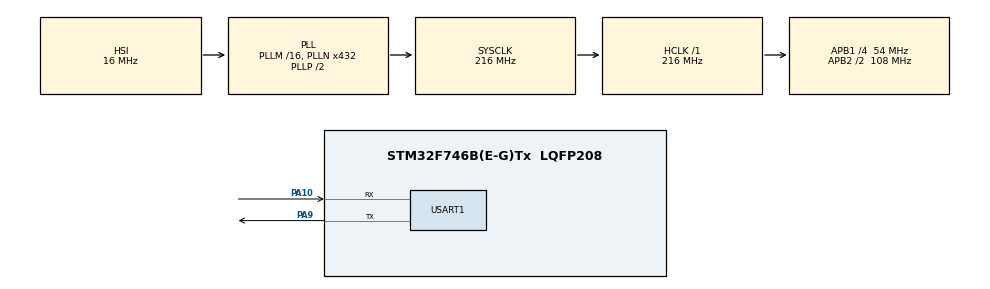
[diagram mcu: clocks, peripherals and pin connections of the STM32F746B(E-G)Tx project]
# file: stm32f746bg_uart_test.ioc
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Mcu.Family=STM32F7
Mcu.Name=STM32F746B(E-G)Tx
Mcu.Package=LQFP208
NVIC.PriorityGroup=NVIC_PRIORITYGROUP_4
PA10.Mode=Asynchronous
PA10.Signal=USART1_RX
PA13.Mode=Serial_Wire
PA13.Signal=SYS_JTMS-SWDIO
PA14.Mode=Serial_Wire
PA14.Signal=SYS_JTCK-SWCLK
PA9.Mode=Asynchronous
PA9.Signal=USART1_TX
ProjectManager.HeapSize=0x200
ProjectManager.StackSize=0x400
ProjectManager.TargetToolchain=EWARM V8
RCC.AHBFreq_Value=216000000
RCC.APB1CLKDivider=RCC_HCLK_DIV4
RCC.APB1Freq_Value=54000000
RCC.APB1TimFreq_Value=108000000
RCC.APB2CLKDivider=RCC_HCLK_DIV2
RCC.APB2Freq_Value=108000000
RCC.APB2TimFreq_Value=216000000
RCC.CortexFreq_Value=216000000
RCC.HCLKFreq_Value=216000000
RCC.HSE_VALUE=25000000
RCC.HSI_VALUE=16000000
RCC.LSE_VALUE=32768
RCC.PLLN=432
RCC.SYSCLKFreq_VALUE=216000000
RCC.SYSCLKSource=RCC_SYSCLKSOURCE_PLLCLK
RCC.USBFreq_Value=216000000
RCC.VCOOutputFreq_Value=432000000
USART1.VirtualMode-Asynchronous=VM_ASYNC
board=custom

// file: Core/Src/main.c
/* USER CODE BEGIN Header */
/**
  ******************************************************************************
  * @file           : main.c
  * @brief          : Main program body
  ******************************************************************************
  * @attention
  *
  * <h2><center>&copy; Copyright (c) 2020 STMicroelectronics.
  * All rights reserved.</center></h2>
  *
  * This software component is licensed by ST under BSD 3-Clause license,
  * the "License"; You may not use this file except in compliance with the
  * License. You may obtain a copy of the License at:
  *                        opensource.org/licenses/BSD-3-Clause
  *
  ******************************************************************************
  */
/* USER CODE END Header */
#include "main.h"
#include "usart.h"
#include "gpio.h"

void SystemClock_Config(void);

/* USER CODE BEGIN 0 */
/* Size of Trasmission buffer */
#define TXBUFFERSIZE                      (COUNTOF(aTxBuffer) - 1)
/* Size of Reception buffer */
#define RXBUFFERSIZE                      TXBUFFERSIZE

/* Exported macro ------------------------------------------------------------*/
#define COUNTOF(__BUFFER__)   (sizeof(__BUFFER__) / sizeof(*(__BUFFER__)))
/* Exported functions ------------------------------------------------------- */

uint8_t aTxBuffer[] = " **** UART_TwoBoards_ComPolling ****  **** UART_TwoBoards_ComPolling ****  **** UART_TwoBoards_ComPolling **** ";

/* Buffer used for reception */
uint8_t aRxBuffer[RXBUFFERSIZE];
/* USER CODE END 0 */

int main(void)
{

  /* MCU Configuration--------------------------------------------------------*/

  /* Reset of all peripherals, Initializes the Flash interface and the Systick. */
  HAL_Init();

  /* Configure the system clock */
  SystemClock_Config();

  /* Initialize all configured peripherals */
  MX_GPIO_Init();
  MX_USART1_UART_Init();

  /* Infinite loop */
  /* USER CODE BEGIN WHILE */
  while (1)
  {
    if(HAL_UART_Transmit(&huart1, (uint8_t*)aTxBuffer, TXBUFFERSIZE, 5000)!= HAL_OK)
    {
        Error_Handler();
    }
    HAL_Delay(3000);
    /* USER CODE END WHILE */

  }
}

void SystemClock_Config(void)
{
  RCC_OscInitTypeDef RCC_OscInitStruct = {0};
  RCC_ClkInitTypeDef RCC_ClkInitStruct = {0};
  RCC_PeriphCLKInitTypeDef PeriphClkInitStruct = {0};

  /** Configure the main internal regulator output voltage
  */
  __HAL_RCC_PWR_CLK_ENABLE();
  __HAL_PWR_VOLTAGESCALING_CONFIG(PWR_REGULATOR_VOLTAGE_SCALE1);
  /** Initializes the RCC Oscillators according to the specified parameters
  * in the RCC_OscInitTypeDef structure.
  */
  RCC_OscInitStruct.OscillatorType = RCC_OSCILLATORTYPE_HSI;
  RCC_OscInitStruct.HSIState = RCC_HSI_ON;
  RCC_OscInitStruct.HSICalibrationValue = RCC_HSICALIBRATION_DEFAULT;
  RCC_OscInitStruct.PLL.PLLState = RCC_PLL_ON;
  RCC_OscInitStruct.PLL.PLLSource = RCC_PLLSOURCE_HSI;
  RCC_OscInitStruct.PLL.PLLM = 16;
  RCC_OscInitStruct.PLL.PLLN = 432;
  RCC_OscInitStruct.PLL.PLLP = RCC_PLLP_DIV2;
  RCC_OscInitStruct.PLL.PLLQ = 2;
  if (HAL_RCC_OscConfig(&RCC_OscInitStruct) != HAL_OK)
  {
    Error_Handler();
  }
  /** Activate the Over-Drive mode
  */
  if (HAL_PWREx_EnableOverDrive() != HAL_OK)
  {
    Error_Handler();
  }
  /** Initializes the CPU, AHB and APB buses clocks
  */
  RCC_ClkInitStruct.ClockType = RCC_CLOCKTYPE_HCLK|RCC_CLOCKTYPE_SYSCLK
                              |RCC_CLOCKTYPE_PCLK1|RCC_CLOCKTYPE_PCLK2;
  RCC_ClkInitStruct.SYSCLKSource = RCC_SYSCLKSOURCE_PLLCLK;
  RCC_ClkInitStruct.AHBCLKDivider = RCC_SYSCLK_DIV1;
  RCC_ClkInitStruct.APB1CLKDivider = RCC_HCLK_DIV4;
  RCC_ClkInitStruct.APB2CLKDivider = RCC_HCLK_DIV2;

  if (HAL_RCC_ClockConfig(&RCC_ClkInitStruct, FLASH_LATENCY_7) != HAL_OK)
  {
    Error_Handler();
  }
  PeriphClkInitStruct.PeriphClockSelection = RCC_PERIPHCLK_USART1;
  PeriphClkInitStruct.Usart1ClockSelection = RCC_USART1CLKSOURCE_PCLK2;
  if (HAL_RCCEx_PeriphCLKConfig(&PeriphClkInitStruct) != HAL_OK)
  {
    Error_Handler();
  }
}

void Error_Handler(void)
{
}

/************************ (C) COPYRIGHT STMicroelectronics *****END OF FILE****/
